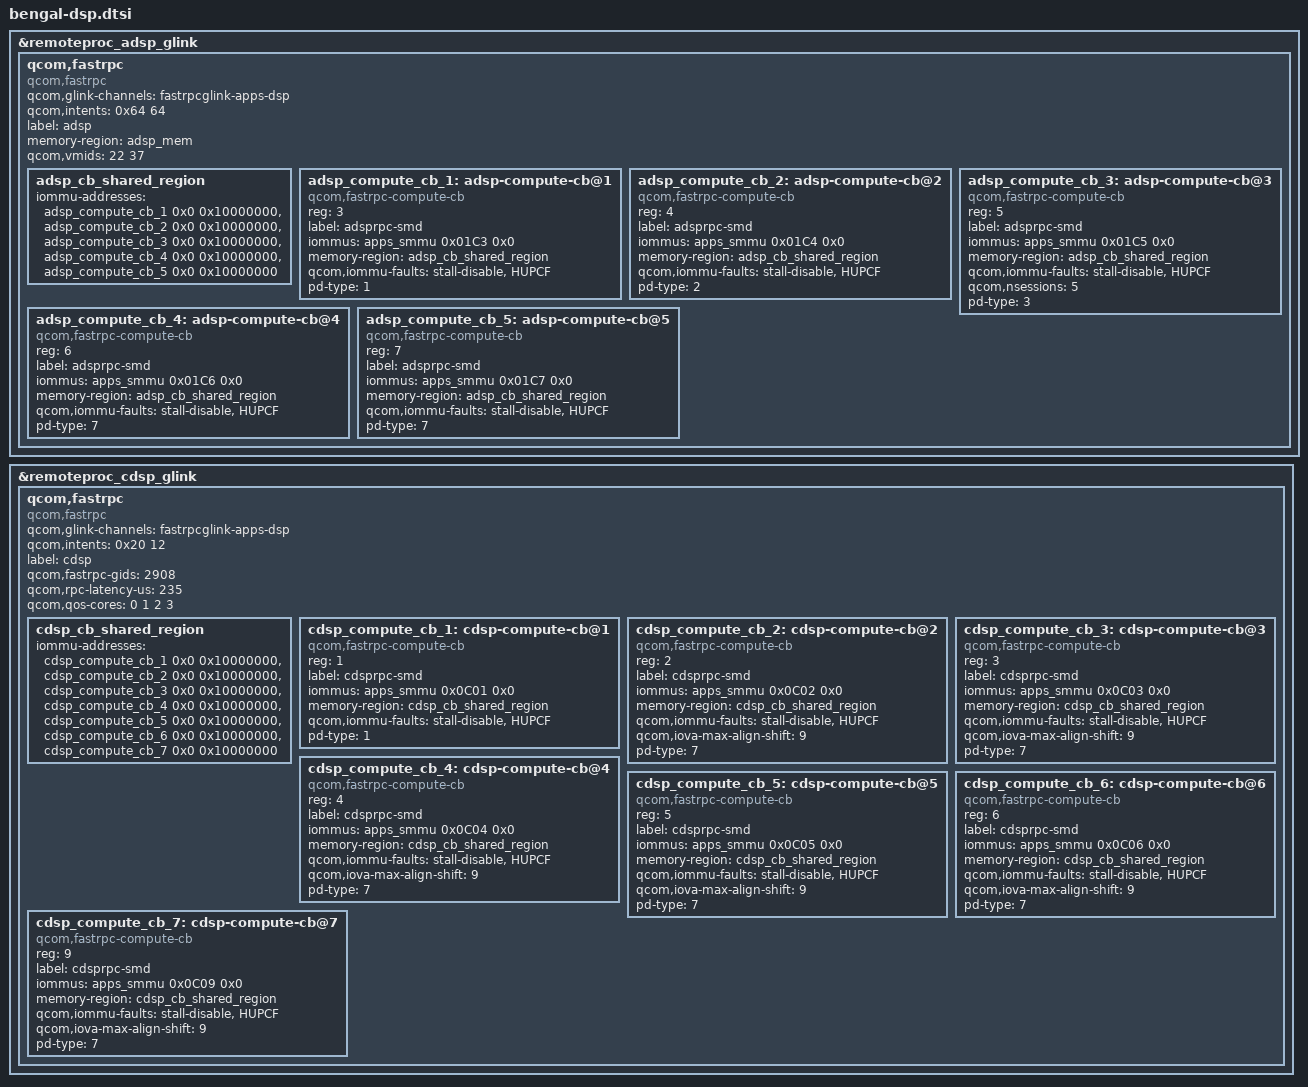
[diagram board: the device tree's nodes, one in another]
// SPDX-License-Identifier: BSD-3-Clause
/*
 * Copyright (c) Qualcomm Technologies, Inc. and/or its subsidiaries.
 */
&remoteproc_adsp_glink {
	qcom,fastrpc {
		compatible = "qcom,fastrpc";
		qcom,glink-channels = "fastrpcglink-apps-dsp";
		qcom,intents = <0x64 64>;
		label = "adsp";
		memory-region = <&adsp_mem>;
		qcom,vmids  = <22 37>;

		adsp_cb_shared_region: adsp_cb_shared_region {
			/* These IOVA regions are unique per context bank */
			iommu-addresses = <&adsp_compute_cb_1 0x0 0x10000000>,
					  <&adsp_compute_cb_2 0x0 0x10000000>,
					  <&adsp_compute_cb_3 0x0 0x10000000>,
					  <&adsp_compute_cb_4 0x0 0x10000000>,
					  <&adsp_compute_cb_5 0x0 0x10000000>;
		};
		adsp_compute_cb_1: adsp-compute-cb@1 {
			compatible = "qcom,fastrpc-compute-cb";
			reg = <3>;
			label = "adsprpc-smd";
                        iommus = <&apps_smmu 0x01C3 0x0>;
                        memory-region = <&adsp_cb_shared_region>;
                        qcom,iommu-faults = "stall-disable", "HUPCF";
			pd-type = <1>;
		};

		adsp_compute_cb_2: adsp-compute-cb@2 {
			compatible = "qcom,fastrpc-compute-cb";
			reg = <4>;
			label = "adsprpc-smd";
                        iommus = <&apps_smmu 0x01C4 0x0>;
                        memory-region = <&adsp_cb_shared_region>;
                        qcom,iommu-faults = "stall-disable", "HUPCF";
                        pd-type = <2>;
		};

		adsp_compute_cb_3: adsp-compute-cb@3 {
			compatible = "qcom,fastrpc-compute-cb";
			reg = <5>;
			label = "adsprpc-smd";
                        iommus = <&apps_smmu 0x01C5 0x0>;
                        memory-region = <&adsp_cb_shared_region>;
                        qcom,iommu-faults = "stall-disable", "HUPCF";
                        qcom,nsessions = <5>;
			pd-type = <3>;
		};

		adsp_compute_cb_4: adsp-compute-cb@4 {
			compatible = "qcom,fastrpc-compute-cb";
			reg = <6>;
			label = "adsprpc-smd";
                        iommus = <&apps_smmu 0x01C6 0x0>;
                        memory-region = <&adsp_cb_shared_region>;
                        qcom,iommu-faults = "stall-disable", "HUPCF";
                        pd-type = <7>;
		};

		adsp_compute_cb_5: adsp-compute-cb@5 {
			compatible = "qcom,fastrpc-compute-cb";
			reg = <7>;
			label = "adsprpc-smd";
                        iommus = <&apps_smmu 0x01C7 0x0>;
                        memory-region = <&adsp_cb_shared_region>;
                        qcom,iommu-faults = "stall-disable", "HUPCF";
                        pd-type = <7>;
		};
	};
};


&remoteproc_cdsp_glink {
	qcom,fastrpc {
		compatible = "qcom,fastrpc";
		qcom,glink-channels = "fastrpcglink-apps-dsp";
		qcom,intents = <0x20 12>;
		label = "cdsp";
		qcom,fastrpc-gids = <2908>;
		qcom,rpc-latency-us = <235>;
                qcom,qos-cores = <0 1 2 3>;

		cdsp_cb_shared_region: cdsp_cb_shared_region {
			/* These IOVA regions are unique per context bank */
			iommu-addresses = <&cdsp_compute_cb_1 0x0 0x10000000>,
					  <&cdsp_compute_cb_2 0x0 0x10000000>,
					  <&cdsp_compute_cb_3 0x0 0x10000000>,
					  <&cdsp_compute_cb_4 0x0 0x10000000>,
					  <&cdsp_compute_cb_5 0x0 0x10000000>,
					  <&cdsp_compute_cb_6 0x0 0x10000000>,
					  <&cdsp_compute_cb_7 0x0 0x10000000>;
		};
		cdsp_compute_cb_1: cdsp-compute-cb@1 {
			compatible = "qcom,fastrpc-compute-cb";
			reg = <1>;
			label = "cdsprpc-smd";
                        iommus = <&apps_smmu 0x0C01 0x0>;
			memory-region = <&cdsp_cb_shared_region>;
			qcom,iommu-faults = "stall-disable" , "HUPCF";
			pd-type = <1>;
		};

		cdsp_compute_cb_2: cdsp-compute-cb@2 {
			compatible = "qcom,fastrpc-compute-cb";
			reg = <2>;
			label = "cdsprpc-smd";
			iommus = <&apps_smmu 0x0C02 0x0>;
			memory-region = <&cdsp_cb_shared_region>;
			qcom,iommu-faults = "stall-disable" , "HUPCF";
			qcom,iova-max-align-shift = <9>;
			pd-type = <7>;
		};

		cdsp_compute_cb_3: cdsp-compute-cb@3 {
			compatible = "qcom,fastrpc-compute-cb";
			reg = <3>;
			label = "cdsprpc-smd";
			iommus = <&apps_smmu 0x0C03 0x0>;
			memory-region = <&cdsp_cb_shared_region>;
			qcom,iommu-faults = "stall-disable" , "HUPCF";
			qcom,iova-max-align-shift = <9>;
			pd-type = <7>;
		};

		cdsp_compute_cb_4: cdsp-compute-cb@4 {
			compatible = "qcom,fastrpc-compute-cb";
			reg = <4>;
			label = "cdsprpc-smd";
			iommus = <&apps_smmu 0x0C04 0x0>;
			memory-region = <&cdsp_cb_shared_region>;
			qcom,iommu-faults = "stall-disable" , "HUPCF";
			qcom,iova-max-align-shift = <9>;
			pd-type = <7>;
		};

		cdsp_compute_cb_5: cdsp-compute-cb@5 {
			compatible = "qcom,fastrpc-compute-cb";
			reg = <5>;
			label = "cdsprpc-smd";
			iommus = <&apps_smmu 0x0C05 0x0>;
			memory-region = <&cdsp_cb_shared_region>;
			qcom,iommu-faults = "stall-disable" , "HUPCF";
			qcom,iova-max-align-shift = <9>;
			pd-type = <7>;
		};

		cdsp_compute_cb_6: cdsp-compute-cb@6 {
			compatible = "qcom,fastrpc-compute-cb";
			reg = <6>;
			label = "cdsprpc-smd";
			iommus = <&apps_smmu 0x0C06 0x0>;
			memory-region = <&cdsp_cb_shared_region>;
			qcom,iommu-faults = "stall-disable" , "HUPCF";
			qcom,iova-max-align-shift = <9>;
			pd-type = <7>;
		};

		cdsp_compute_cb_7: cdsp-compute-cb@7 {
			compatible = "qcom,fastrpc-compute-cb";
			reg = <9>;
			label = "cdsprpc-smd";
			iommus = <&apps_smmu 0x0C09 0x0>;
			memory-region = <&cdsp_cb_shared_region>;
			qcom,iommu-faults = "stall-disable" , "HUPCF";
			qcom,iova-max-align-shift = <9>;
			pd-type = <7>;
		};
	};
};
